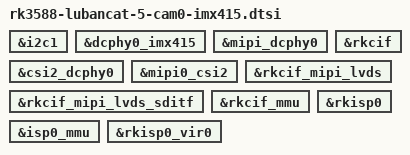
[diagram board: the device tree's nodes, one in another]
// SPDX-License-Identifier: (GPL-2.0+ OR MIT)
/*
 * Copyright (c) 2020 Rockchip Electronics Co., Ltd.
 *
 */

&i2c1 {
	status = "okay";
};

&dcphy0_imx415 {
	status = "okay";
};

&mipi_dcphy0 {
	status = "okay";
};

&csi2_dcphy0 {
	status = "okay";
};

&mipi0_csi2 {
	status = "okay";
};

&rkcif {
	status = "okay";
};

&rkcif_mipi_lvds {
	status = "okay";
};

&rkcif_mipi_lvds_sditf {
	status = "okay";
};

&rkcif_mmu {
	status = "okay";
};

&rkisp0 {
	status = "okay";
};

&isp0_mmu {
	status = "okay";
};

&rkisp0_vir0 {
	status = "okay";
};

